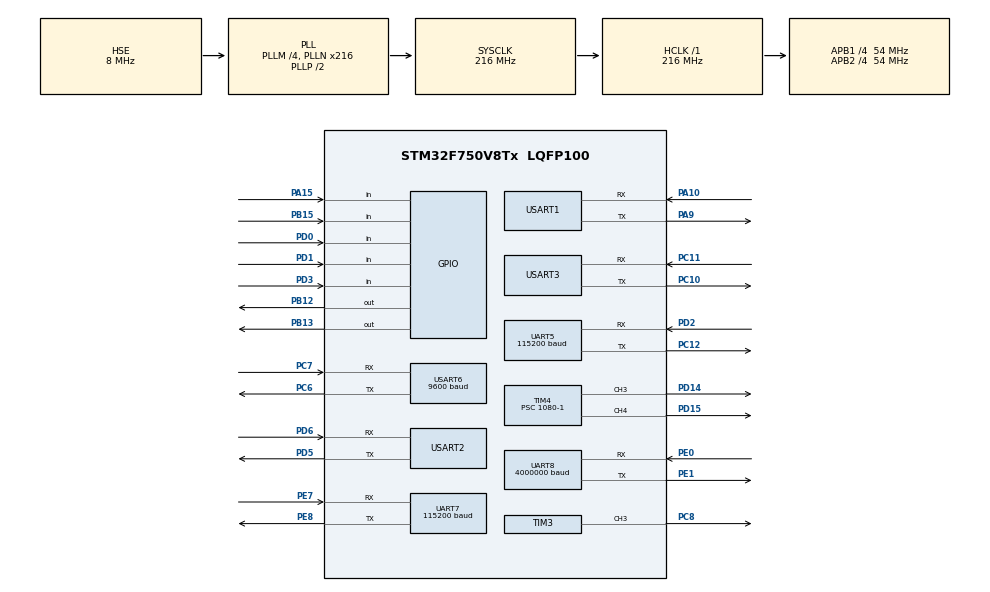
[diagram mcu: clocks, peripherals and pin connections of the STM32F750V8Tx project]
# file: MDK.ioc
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Dma.Request0=USART2_RX
Dma.Request1=USART3_RX
Dma.Request2=USART3_TX
Dma.Request3=UART7_RX
Dma.UART7_RX.3.Direction=DMA_PERIPH_TO_MEMORY
Dma.UART7_RX.3.FIFOMode=DMA_FIFOMODE_DISABLE
Dma.UART7_RX.3.Instance=DMA1_Stream3
Dma.UART7_RX.3.MemDataAlignment=DMA_MDATAALIGN_BYTE
Dma.UART7_RX.3.MemInc=DMA_MINC_ENABLE
Dma.UART7_RX.3.Mode=DMA_NORMAL
Dma.UART7_RX.3.PeriphDataAlignment=DMA_PDATAALIGN_BYTE
Dma.UART7_RX.3.PeriphInc=DMA_PINC_DISABLE
Dma.UART7_RX.3.Priority=DMA_PRIORITY_MEDIUM
Dma.USART2_RX.0.Direction=DMA_PERIPH_TO_MEMORY
Dma.USART2_RX.0.FIFOMode=DMA_FIFOMODE_DISABLE
Dma.USART2_RX.0.Instance=DMA1_Stream5
Dma.USART2_RX.0.MemDataAlignment=DMA_MDATAALIGN_BYTE
Dma.USART2_RX.0.MemInc=DMA_MINC_ENABLE
Dma.USART2_RX.0.Mode=DMA_CIRCULAR
Dma.USART2_RX.0.PeriphDataAlignment=DMA_PDATAALIGN_BYTE
Dma.USART2_RX.0.PeriphInc=DMA_PINC_DISABLE
Dma.USART2_RX.0.Priority=DMA_PRIORITY_MEDIUM
Dma.USART3_RX.1.Direction=DMA_PERIPH_TO_MEMORY
Dma.USART3_RX.1.FIFOMode=DMA_FIFOMODE_DISABLE
Dma.USART3_RX.1.Instance=DMA1_Stream1
Dma.USART3_RX.1.MemDataAlignment=DMA_MDATAALIGN_BYTE
Dma.USART3_RX.1.MemInc=DMA_MINC_ENABLE
Dma.USART3_RX.1.Mode=DMA_NORMAL
Dma.USART3_RX.1.PeriphDataAlignment=DMA_PDATAALIGN_BYTE
Dma.USART3_RX.1.PeriphInc=DMA_PINC_DISABLE
Dma.USART3_RX.1.Priority=DMA_PRIORITY_MEDIUM
Dma.USART3_TX.2.Direction=DMA_MEMORY_TO_PERIPH
Dma.USART3_TX.2.FIFOMode=DMA_FIFOMODE_DISABLE
Dma.USART3_TX.2.Instance=DMA1_Stream4
Dma.USART3_TX.2.MemDataAlignment=DMA_MDATAALIGN_BYTE
Dma.USART3_TX.2.MemInc=DMA_MINC_ENABLE
Dma.USART3_TX.2.Mode=DMA_NORMAL
Dma.USART3_TX.2.PeriphDataAlignment=DMA_PDATAALIGN_BYTE
Dma.USART3_TX.2.PeriphInc=DMA_PINC_DISABLE
Dma.USART3_TX.2.Priority=DMA_PRIORITY_MEDIUM
FREERTOS.INCLUDE_eTaskGetState=1
FREERTOS.INCLUDE_vTaskDelayUntil=1
FREERTOS.Tasks01=defaultTask,0,128,StartDefaultTask,Default,NULL,Dynamic,NULL,NULL
Mcu.Family=STM32F7
Mcu.Name=STM32F750V8Tx
Mcu.Package=LQFP100
NVIC.DMA1_Stream1_IRQn=true\:5\:0\:false\:false\:true\:true\:false\:true\:true
NVIC.DMA1_Stream3_IRQn=true\:5\:0\:false\:false\:true\:true\:false\:true\:true
NVIC.DMA1_Stream4_IRQn=true\:5\:0\:false\:false\:true\:true\:false\:true\:true
NVIC.DMA1_Stream5_IRQn=true\:5\:0\:false\:false\:true\:true\:false\:true\:true
NVIC.PriorityGroup=NVIC_PRIORITYGROUP_4
NVIC.TIM6_DAC_IRQn=true\:1\:0\:true\:false\:true\:true\:true\:true\:true
NVIC.TIM8_TRG_COM_TIM14_IRQn=true\:0\:0\:false\:false\:true\:false\:false\:true\:true
NVIC.TimeBase=TIM8_TRG_COM_TIM14_IRQn
NVIC.TimeBaseIP=TIM14
NVIC.UART5_IRQn=true\:2\:0\:true\:false\:true\:true\:true\:true\:true
NVIC.UART7_IRQn=true\:2\:0\:true\:false\:true\:true\:true\:true\:true
NVIC.UART8_IRQn=true\:2\:0\:true\:false\:true\:true\:true\:true\:true
NVIC.USART1_IRQn=true\:2\:0\:true\:false\:true\:true\:true\:true\:true
NVIC.USART2_IRQn=true\:2\:0\:true\:false\:true\:true\:true\:true\:true
NVIC.USART3_IRQn=true\:2\:0\:true\:false\:true\:true\:true\:true\:true
NVIC.USART6_IRQn=true\:1\:0\:true\:false\:true\:true\:true\:true\:true
PA10.Mode=Asynchronous
PA10.Signal=USART1_RX
PA13.Mode=Serial_Wire
PA13.Signal=SYS_JTMS-SWDIO
PA14.Mode=Serial_Wire
PA14.Signal=SYS_JTCK-SWCLK
PA15.Signal=GPIO_Input
PA9.Mode=Asynchronous
PA9.Signal=USART1_TX
PB12.Signal=GPIO_Output
PB13.Signal=GPIO_Output
PB15.Signal=GPIO_Input
PC10.Mode=Asynchronous
PC10.Signal=USART3_TX
PC11.Mode=Asynchronous
PC11.Signal=USART3_RX
PC12.Mode=Asynchronous
PC12.Signal=UART5_TX
PC6.Mode=Asynchronous
PC6.Signal=USART6_TX
PC7.Mode=Asynchronous
PC7.Signal=USART6_RX
PC8.Signal=S_TIM3_CH3
PD0.Signal=GPIO_Input
PD1.Signal=GPIO_Input
PD14.Signal=S_TIM4_CH3
PD15.Signal=S_TIM4_CH4
PD2.Mode=Asynchronous
PD2.Signal=UART5_RX
PD3.Signal=GPIO_Input
PD5.Mode=Asynchronous
PD5.Signal=USART2_TX
PD6.Mode=Asynchronous
PD6.Signal=USART2_RX
PE0.Mode=Asynchronous
PE0.Signal=UART8_RX
PE1.Mode=Asynchronous
PE1.Signal=UART8_TX
PE7.Mode=Asynchronous
PE7.Signal=UART7_RX
PE8.Mode=Asynchronous
PE8.Signal=UART7_TX
PH0/OSC_IN.Mode=HSE-External-Oscillator
PH0/OSC_IN.Signal=RCC_OSC_IN
PH1/OSC_OUT.Mode=HSE-External-Oscillator
PH1/OSC_OUT.Signal=RCC_OSC_OUT
ProjectManager.HeapSize=0x200
ProjectManager.StackSize=0x400
ProjectManager.TargetToolchain=MDK-ARM V5.32
RCC.AHBFreq_Value=216000000
RCC.APB1CLKDivider=RCC_HCLK_DIV4
RCC.APB1Freq_Value=54000000
RCC.APB1TimFreq_Value=108000000
RCC.APB2CLKDivider=RCC_HCLK_DIV4
RCC.APB2Freq_Value=54000000
RCC.APB2TimFreq_Value=108000000
RCC.CortexFreq_Value=216000000
RCC.HCLKFreq_Value=216000000
RCC.HSE_VALUE=8000000
RCC.HSI_VALUE=16000000
RCC.LSE_VALUE=32768
RCC.PLLM=4
RCC.PLLN=216
RCC.PLLSourceVirtual=RCC_PLLSOURCE_HSE
RCC.SYSCLKFreq_VALUE=216000000
RCC.SYSCLKSource=RCC_SYSCLKSOURCE_PLLCLK
RCC.UART8CLockSelection=RCC_UART8CLKSOURCE_SYSCLK
RCC.USBFreq_Value=216000000
RCC.VCOOutputFreq_Value=432000000
SH.S_TIM3_CH3.0=TIM3_CH3,PWM Generation3 CH3
SH.S_TIM4_CH3.0=TIM4_CH3,PWM Generation3 CH3
SH.S_TIM4_CH4.0=TIM4_CH4,PWM Generation4 CH4
TIM3.Channel-PWM\ Generation3\ CH3=TIM_CHANNEL_3
TIM3.Period=2000-1
TIM3.Prescaler=1080-1
TIM4.Channel-PWM\ Generation3\ CH3=TIM_CHANNEL_3
TIM4.Channel-PWM\ Generation4\ CH4=TIM_CHANNEL_4
TIM4.Period=2000-1
TIM4.Prescaler=1080-1
TIM6.AutoReloadPreload=TIM_AUTORELOAD_PRELOAD_ENABLE
TIM6.Period=100-1
TIM6.Prescaler=1080-1
UART5.BaudRate=115200
UART7.BaudRate=115200
UART8.BaudRate=4000000
USART1.VirtualMode-Asynchronous=VM_ASYNC
USART2.VirtualMode-Asynchronous=VM_ASYNC
USART3.VirtualMode-Asynchronous=VM_ASYNC
USART6.BaudRate=9600
USART6.VirtualMode=VM_ASYNC
VP_FREERTOS_VS_CMSIS_V1.Mode=CMSIS_V1
VP_SYS_VS_tim14.Mode=TIM14
VP_TIM6_VS_ClockSourceINT.Mode=Enable_Timer
board=custom

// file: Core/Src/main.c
/* USER CODE BEGIN Header */
/**
  ******************************************************************************
  * @file           : main.c
  * @brief          : Main program body
  ******************************************************************************
  * @attention
  *
  * <h2><center>&copy; Copyright (c) 2022 STMicroelectronics.
  * All rights reserved.</center></h2>
  *
  * This software component is licensed by ST under BSD 3-Clause license,
  * the "License"; You may not use this file except in compliance with the
  * License. You may obtain a copy of the License at:
  *                        opensource.org/licenses/BSD-3-Clause
  *
  ******************************************************************************
  */
/* USER CODE END Header */
#include "main.h"
#include "cmsis_os.h"
#include "dma.h"
#include "tim.h"
#include "usart.h"
#include "gpio.h"

/* USER CODE BEGIN Includes */
#include "delay.h"
/* USER CODE END Includes */

/* USER CODE BEGIN PTD */
int x,y,z,a = 0;
/* USER CODE END PTD */

/* USER CODE BEGIN PM */
extern volatile uint16_t delaytime;
/* USER CODE END PM */

void SystemClock_Config(void);
void MX_FREERTOS_Init(void);

int main(void)
{

  /* MCU Configuration--------------------------------------------------------*/

  /* Reset of all peripherals, Initializes the Flash interface and the Systick. */
  HAL_Init();

  /* USER CODE BEGIN Init */
	HAL_DeInit();
  /* USER CODE END Init */

  /* Configure the system clock */
  SystemClock_Config();

  /* Initialize all configured peripherals */
  MX_GPIO_Init();
  MX_DMA_Init();
  MX_TIM6_Init();
  MX_UART5_Init();
  MX_UART7_Init();
  MX_UART8_Init();
  MX_USART2_UART_Init();
  MX_USART3_UART_Init();
  MX_USART6_UART_Init();
  MX_USART1_UART_Init();
  MX_TIM4_Init();
  MX_TIM3_Init();
  /* USER CODE BEGIN 2 */
//    ///////��ʼ��////////
//		Delay_Init();
//		//HAL_TIM_Base_Start_IT(&htim6);//��ʼ
//		MOTOR_Init();
//    Gyro_Init();
//    QR_sense_init();
//    POSTION_init();
//    M8010_init();
//    HAL_TIM_PWM_Start(&htim3,TIM_CHANNEL_3);
//    HAL_TIM_PWM_Start(&htim4,TIM_CHANNEL_4);
//    //////��ʼ�����//////
//    Delay_ms(2);
//    read_init_postion();
//    HMI_SEND();
	  //printf("��ʼ�����");
    //GLOBAL_DATA.CHANHE_SAGE = 0;//�رռ���
//  catch_yuan_pan_ji(red);
//	M8010_send(0);
//	HAL_Delay(1000);
//	M8010_send(-161);
//	claw_move_1(1);
//	send_NX(RED_CIRCLE);
//	locate_3();
//  catch_half_stage(red);
//  first_one();
  /* USER CODE END 2 */

  /* Call init function for freertos objects (in freertos.c) */
  MX_FREERTOS_Init();
  /* Start scheduler */
  osKernelStart();

  /* We should never get here as control is now taken by the scheduler */
  /* Infinite loop */
  while (1)
  {

  }
}

void SystemClock_Config(void)
{
  RCC_OscInitTypeDef RCC_OscInitStruct = {0};
  RCC_ClkInitTypeDef RCC_ClkInitStruct = {0};
  RCC_PeriphCLKInitTypeDef PeriphClkInitStruct = {0};

  /** Configure the main internal regulator output voltage
  */
  __HAL_RCC_PWR_CLK_ENABLE();
  __HAL_PWR_VOLTAGESCALING_CONFIG(PWR_REGULATOR_VOLTAGE_SCALE1);
  /** Initializes the RCC Oscillators according to the specified parameters
  * in the RCC_OscInitTypeDef structure.
  */
  RCC_OscInitStruct.OscillatorType = RCC_OSCILLATORTYPE_HSE;
  RCC_OscInitStruct.HSEState = RCC_HSE_ON;
  RCC_OscInitStruct.PLL.PLLState = RCC_PLL_ON;
  RCC_OscInitStruct.PLL.PLLSource = RCC_PLLSOURCE_HSE;
  RCC_OscInitStruct.PLL.PLLM = 4;
  RCC_OscInitStruct.PLL.PLLN = 216;
  RCC_OscInitStruct.PLL.PLLP = RCC_PLLP_DIV2;
  RCC_OscInitStruct.PLL.PLLQ = 2;
  if (HAL_RCC_OscConfig(&RCC_OscInitStruct) != HAL_OK)
  {
    Error_Handler();
  }
  /** Activate the Over-Drive mode
  */
  if (HAL_PWREx_EnableOverDrive() != HAL_OK)
  {
    Error_Handler();
  }
  /** Initializes the CPU, AHB and APB buses clocks
  */
  RCC_ClkInitStruct.ClockType = RCC_CLOCKTYPE_HCLK|RCC_CLOCKTYPE_SYSCLK
                              |RCC_CLOCKTYPE_PCLK1|RCC_CLOCKTYPE_PCLK2;
  RCC_ClkInitStruct.SYSCLKSource = RCC_SYSCLKSOURCE_PLLCLK;
  RCC_ClkInitStruct.AHBCLKDivider = RCC_SYSCLK_DIV1;
  RCC_ClkInitStruct.APB1CLKDivider = RCC_HCLK_DIV4;
  RCC_ClkInitStruct.APB2CLKDivider = RCC_HCLK_DIV4;

  if (HAL_RCC_ClockConfig(&RCC_ClkInitStruct, FLASH_LATENCY_7) != HAL_OK)
  {
    Error_Handler();
  }
  PeriphClkInitStruct.PeriphClockSelection = RCC_PERIPHCLK_USART1|RCC_PERIPHCLK_USART2
                              |RCC_PERIPHCLK_USART3|RCC_PERIPHCLK_USART6
                              |RCC_PERIPHCLK_UART5|RCC_PERIPHCLK_UART7
                              |RCC_PERIPHCLK_UART8;
  PeriphClkInitStruct.Usart1ClockSelection = RCC_USART1CLKSOURCE_PCLK2;
  PeriphClkInitStruct.Usart2ClockSelection = RCC_USART2CLKSOURCE_PCLK1;
  PeriphClkInitStruct.Usart3ClockSelection = RCC_USART3CLKSOURCE_PCLK1;
  PeriphClkInitStruct.Uart5ClockSelection = RCC_UART5CLKSOURCE_PCLK1;
  PeriphClkInitStruct.Usart6ClockSelection = RCC_USART6CLKSOURCE_PCLK2;
  PeriphClkInitStruct.Uart7ClockSelection = RCC_UART7CLKSOURCE_PCLK1;
  PeriphClkInitStruct.Uart8ClockSelection = RCC_UART8CLKSOURCE_SYSCLK;
  if (HAL_RCCEx_PeriphCLKConfig(&PeriphClkInitStruct) != HAL_OK)
  {
    Error_Handler();
  }
}

 /**
  * @brief  Period elapsed callback in non blocking mode
  * @note   This function is called  when TIM14 interrupt took place, inside
  * HAL_TIM_IRQHandler(). It makes a direct call to HAL_IncTick() to increment
  * a global variable "uwTick" used as application time base.
  * @param  htim : TIM handle
  * @retval None
  */
void HAL_TIM_PeriodElapsedCallback(TIM_HandleTypeDef *htim)
{
  if (htim->Instance == TIM14) {
    HAL_IncTick();
  }
  /* USER CODE BEGIN Callback 1 */
	if (htim->Instance == TIM6) { // �жϴ����жϵĶ�ʱ���Ƿ��� htim6
					delaytime++;
					__HAL_TIM_CLEAR_IT(&htim6, TIM_IT_UPDATE);//����жϱ�־λ
			}
  /* USER CODE END Callback 1 */
}

void Error_Handler(void)
{
  __disable_irq();
  while (1)
  {
  }
}

/************************ (C) COPYRIGHT STMicroelectronics *****END OF FILE****/

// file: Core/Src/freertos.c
/* USER CODE BEGIN Header */
/**
  ******************************************************************************
  * File Name          : freertos.c
  * Description        : Code for freertos applications
  ******************************************************************************
  * @attention
  *
  * <h2><center>&copy; Copyright (c) 2024 STMicroelectronics.
  * All rights reserved.</center></h2>
  *
  * This software component is licensed by ST under Ultimate Liberty license
  * SLA0044, the "License"; You may not use this file except in compliance with
  * the License. You may obtain a copy of the License at:
  *                             www.st.com/SLA0044
  *
  ******************************************************************************
  */
/* USER CODE END Header */

#include "FreeRTOS.h"
#include "task.h"
#include "main.h"
#include "cmsis_os.h"

/* USER CODE BEGIN Includes */
#include "start_task.h"
/* USER CODE END Includes */

osThreadId defaultTaskHandle;

void StartDefaultTask(void const * argument);

void MX_FREERTOS_Init(void); /* (MISRA C 2004 rule 8.1) */

/* GetIdleTaskMemory prototype (linked to static allocation support) */
void vApplicationGetIdleTaskMemory( StaticTask_t **ppxIdleTaskTCBBuffer, StackType_t **ppxIdleTaskStackBuffer, uint32_t *pulIdleTaskStackSize );

/* USER CODE BEGIN GET_IDLE_TASK_MEMORY */
static StaticTask_t xIdleTaskTCBBuffer;
static StackType_t xIdleStack[configMINIMAL_STACK_SIZE];

void vApplicationGetIdleTaskMemory( StaticTask_t **ppxIdleTaskTCBBuffer, StackType_t **ppxIdleTaskStackBuffer, uint32_t *pulIdleTaskStackSize )
{
  *ppxIdleTaskTCBBuffer = &xIdleTaskTCBBuffer;
  *ppxIdleTaskStackBuffer = &xIdleStack[0];
  *pulIdleTaskStackSize = configMINIMAL_STACK_SIZE;
  /* place for user code */
}
/* USER CODE END GET_IDLE_TASK_MEMORY */

void MX_FREERTOS_Init(void) {

  /* Create the thread(s) */
  /* definition and creation of defaultTask */
  osThreadDef(defaultTask, StartDefaultTask, osPriorityNormal, 0, 128);
  defaultTaskHandle = osThreadCreate(osThread(defaultTask), NULL);

  /* USER CODE BEGIN RTOS_THREADS */
  /* add threads, ... */
	Start_Task_Create();
  /* USER CODE END RTOS_THREADS */

}

void StartDefaultTask(void const * argument)
{
  for(;;)
  {
    osDelay(1);
  }
}

/************************ (C) COPYRIGHT STMicroelectronics *****END OF FILE****/
